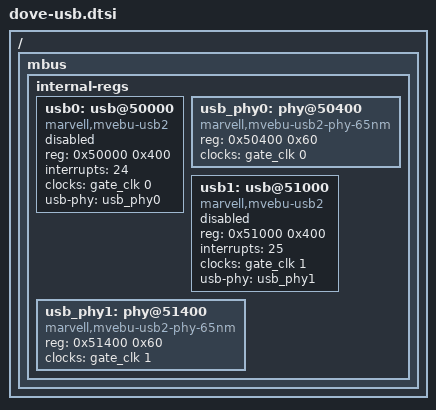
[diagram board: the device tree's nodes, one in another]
/ {
	mbus {
		internal-regs {
			/delete-node/ usb-host@50000;
			/delete-node/ usb-host@51000;

			usb0: usb@50000 {
				compatible = "marvell,mvebu-usb2";
				reg = <0x50000 0x400>;
				interrupts = <24>;
				clocks = <&gate_clk 0>;
				usb-phy = <&usb_phy0>;
				status = "disabled";
			};

			usb_phy0: phy@50400 {
				compatible = "marvell,mvebu-usb2-phy-65nm";
				reg = <0x50400 0x60>;
				clocks = <&gate_clk 0>;
				#phy-cells = <0>;
				status = "okay";
			};

			usb1: usb@51000 {
				compatible = "marvell,mvebu-usb2";
				reg = <0x51000 0x400>;
				interrupts = <25>;
				clocks = <&gate_clk 1>;
				usb-phy = <&usb_phy1>;
				status = "disabled";
			};

			usb_phy1: phy@51400 {
				compatible = "marvell,mvebu-usb2-phy-65nm";
				reg = <0x51400 0x60>;
				clocks = <&gate_clk 1>;
				#phy-cells = <0>;
				status = "okay";
			};
		};
	};
};
